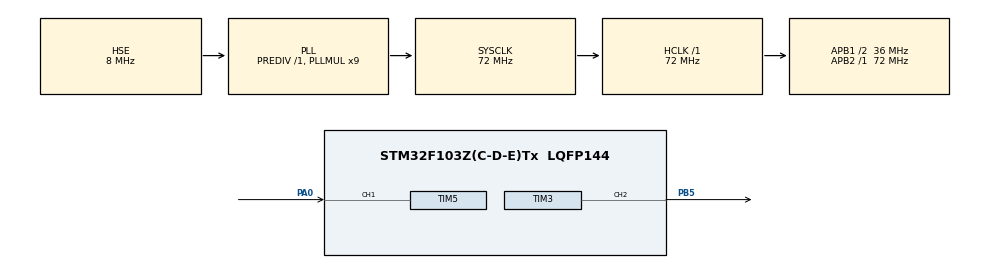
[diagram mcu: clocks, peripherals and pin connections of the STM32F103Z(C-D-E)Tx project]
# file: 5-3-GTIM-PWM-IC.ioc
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Mcu.Family=STM32F1
Mcu.Name=STM32F103Z(C-D-E)Tx
Mcu.Package=LQFP144
NVIC.PriorityGroup=NVIC_PRIORITYGROUP_4
NVIC.TIM3_IRQn=true\:0\:0\:false\:false\:true\:true\:true\:true
NVIC.TIM5_IRQn=true\:0\:0\:false\:false\:true\:true\:true\:true
OSC_IN.Mode=HSE-External-Oscillator
OSC_IN.Signal=RCC_OSC_IN
OSC_OUT.Mode=HSE-External-Oscillator
OSC_OUT.Signal=RCC_OSC_OUT
PA0-WKUP.Signal=S_TIM5_CH1
PA13.Mode=Serial_Wire
PA13.Signal=SYS_JTMS-SWDIO
PA14.Mode=Serial_Wire
PA14.Signal=SYS_JTCK-SWCLK
PB5.Signal=S_TIM3_CH2
ProjectManager.HeapSize=0x200
ProjectManager.StackSize=0x400
ProjectManager.TargetToolchain=MDK-ARM V5.32
RCC.AHBFreq_Value=72000000
RCC.APB1CLKDivider=RCC_HCLK_DIV2
RCC.APB1Freq_Value=36000000
RCC.APB1TimFreq_Value=72000000
RCC.APB2Freq_Value=72000000
RCC.APB2TimFreq_Value=72000000
RCC.HCLKFreq_Value=72000000
RCC.PLLMUL=RCC_PLL_MUL9
RCC.PLLSourceVirtual=RCC_PLLSOURCE_HSE
RCC.SYSCLKFreq_VALUE=72000000
RCC.SYSCLKSource=RCC_SYSCLKSOURCE_PLLCLK
RCC.USBFreq_Value=72000000
SH.S_TIM3_CH2.0=TIM3_CH2,PWM Generation2 CH2
SH.S_TIM5_CH1.0=TIM5_CH1,Input_Capture1_from_TI1
TIM3.Channel-PWM\ Generation2\ CH2=TIM_CHANNEL_2
TIM3.OCPolarity_2=TIM_OCPOLARITY_LOW
TIM3.Period=999
TIM3.Prescaler=71
TIM3.Pulse-PWM\ Generation2\ CH2=500
TIM5.Channel-Input_Capture1_from_TI1=TIM_CHANNEL_1
TIM5.Prescaler=71
VP_TIM5_VS_ClockSourceINT.Mode=Internal
board=custom

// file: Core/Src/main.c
/* USER CODE BEGIN Header */
/**
  ******************************************************************************
  * @file           : main.c
  * @brief          : Main program body
  ******************************************************************************
  * @attention
  *
  * Copyright (c) 2026 STMicroelectronics.
  * All rights reserved.
  *
  * This software is licensed under terms that can be found in the LICENSE file
  * in the root directory of this software component.
  * If no LICENSE file comes with this software, it is provided AS-IS.
  *
  ******************************************************************************
  */
/* USER CODE END Header */
#include "main.h"
#include "tim.h"
#include "gpio.h"

void SystemClock_Config(void);

int main(void)
{

  /* MCU Configuration--------------------------------------------------------*/

  /* Reset of all peripherals, Initializes the Flash interface and the Systick. */
  HAL_Init();

  /* Configure the system clock */
  SystemClock_Config();

  /* Initialize all configured peripherals */
  MX_GPIO_Init();
  MX_TIM3_Init();
  MX_TIM5_Init();
  /* USER CODE BEGIN 2 */

HAL_TIM_PWM_Start(&htim3, TIM_CHANNEL_2);    //启动发送
HAL_TIM_IC_Start_IT(&htim5, TIM_CHANNEL_1);     //启动接收(带中断)

      uint16_t pwm_val = 0;
      uint8_t state = 1;

  /* USER CODE END 2 */

  /* Infinite loop */
  /* USER CODE BEGIN WHILE */
  while (1)
  {

      // 写呼吸灯逻辑
      while(1)
      {
      if(state)
          pwm_val++;
      else
          pwm_val--;
      if(pwm_val >= 950)
          state = 0;
      if(pwm_val <= 10)
          state = 1;

      __HAL_TIM_SET_COMPARE(&htim3, TIM_CHANNEL_2, pwm_val);

      HAL_Delay(1);    //调整呼吸速度
      }
    /* USER CODE END WHILE */

  }
}

void SystemClock_Config(void)
{
  RCC_OscInitTypeDef RCC_OscInitStruct = {0};
  RCC_ClkInitTypeDef RCC_ClkInitStruct = {0};

  /** Initializes the RCC Oscillators according to the specified parameters
  * in the RCC_OscInitTypeDef structure.
  */
  RCC_OscInitStruct.OscillatorType = RCC_OSCILLATORTYPE_HSE;
  RCC_OscInitStruct.HSEState = RCC_HSE_ON;
  RCC_OscInitStruct.HSEPredivValue = RCC_HSE_PREDIV_DIV1;
  RCC_OscInitStruct.HSIState = RCC_HSI_ON;
  RCC_OscInitStruct.PLL.PLLState = RCC_PLL_ON;
  RCC_OscInitStruct.PLL.PLLSource = RCC_PLLSOURCE_HSE;
  RCC_OscInitStruct.PLL.PLLMUL = RCC_PLL_MUL9;
  if (HAL_RCC_OscConfig(&RCC_OscInitStruct) != HAL_OK)
  {
    Error_Handler();
  }

  /** Initializes the CPU, AHB and APB buses clocks
  */
  RCC_ClkInitStruct.ClockType = RCC_CLOCKTYPE_HCLK|RCC_CLOCKTYPE_SYSCLK
                              |RCC_CLOCKTYPE_PCLK1|RCC_CLOCKTYPE_PCLK2;
  RCC_ClkInitStruct.SYSCLKSource = RCC_SYSCLKSOURCE_PLLCLK;
  RCC_ClkInitStruct.AHBCLKDivider = RCC_SYSCLK_DIV1;
  RCC_ClkInitStruct.APB1CLKDivider = RCC_HCLK_DIV2;
  RCC_ClkInitStruct.APB2CLKDivider = RCC_HCLK_DIV1;

  if (HAL_RCC_ClockConfig(&RCC_ClkInitStruct, FLASH_LATENCY_2) != HAL_OK)
  {
    Error_Handler();
  }
}

/* USER CODE BEGIN 4 */

uint32_t val1 = 0, val2 = 0, high_time = 0;
uint8_t flag = 0;

void HAL_TIM_IC_CaptureCallback(TIM_HandleTypeDef *htim)
{
    if(htim->Instance == TIM5)
    {
        if(flag == 0)
        {
        val1 = HAL_TIM_ReadCapturedValue(htim, TIM_CHANNEL_1);
        __HAL_TIM_SET_CAPTUREPOLARITY(htim, TIM_CHANNEL_1, TIM_ICPOLARITY_FALLING);
        flag = 1;
        }
        else if(flag == 1)
        {
        val2 = HAL_TIM_ReadCapturedValue(htim, TIM_CHANNEL_1);
        high_time = (val1 > val2) ? (val1 - val2) : (65535 - val1 + val2);
        __HAL_TIM_SET_CAPTUREPOLARITY(htim, TIM_CHANNEL_1, TIM_ICPOLARITY_RISING);
        flag = 0;
        }
    }
}

/* USER CODE END 4 */

void Error_Handler(void)
{
  __disable_irq();
  while (1)
  {
  }
}
